# DDR32SS0_CTLPHY_WRAP_CTL_CFG_CTLCFG register map
Vendor: Texas Instruments
Registers are 32-bit, read-write, reset 0x0 unless marked. A register's access mark holds for its fields unless they carry their own. Offsets are as the file gives them; [hi:lo] are bit positions; lines under a group give offsets from that group; {n}, {i} and the like mark numbered series.

## DDR32SS0_CTLPHY_WRAP_CTL_CFG_CTLCFG (part 2 of 11)
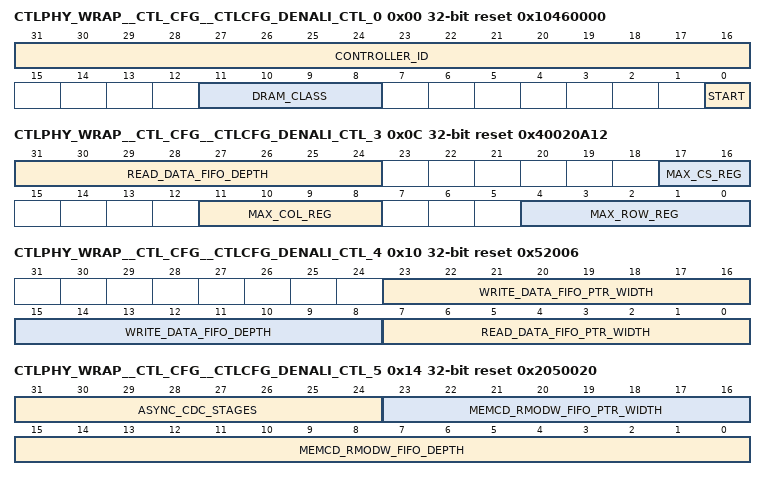
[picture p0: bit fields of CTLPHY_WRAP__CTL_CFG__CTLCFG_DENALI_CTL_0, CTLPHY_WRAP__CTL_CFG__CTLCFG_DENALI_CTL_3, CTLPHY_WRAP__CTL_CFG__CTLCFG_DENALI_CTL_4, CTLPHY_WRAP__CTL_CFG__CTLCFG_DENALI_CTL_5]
0x00 CTLPHY_WRAP__CTL_CFG__CTLCFG_DENALI_CTL_0 access per field reset 0x10460000
  [31:16] CONTROLLER_ID ro — Holds the controller product id number. READ-ONLY
  [11:8] DRAM_CLASS rw — Defines the class of DRAM memory which is connected to the controller.
  [0] START rw — Initiate command processing in the controller. Set to 1 to initiate.
0x04 CTLPHY_WRAP__CTL_CFG__CTLCFG_DENALI_CTL_1 ro reset 0x617AD652
  [31:0] CONTROLLER_VERSION_0 — Holds the controller version id. READ-ONLY
0x08 CTLPHY_WRAP__CTL_CFG__CTLCFG_DENALI_CTL_2 ro reset 0x409E81
  [31:0] CONTROLLER_VERSION_1 — Holds the controller version id. READ-ONLY
0x0C CTLPHY_WRAP__CTL_CFG__CTLCFG_DENALI_CTL_3 ro reset 0x40020A12
  [31:24] READ_DATA_FIFO_DEPTH — Reports the depth of the controller core read data queue. READ-ONLY
  [17:16] MAX_CS_REG — Holds the maximum number of chip selects available. READ-ONLY
  [11:8] MAX_COL_REG — Holds the maximum width of column address in DRAMs. READ-ONLY
  [4:0] MAX_ROW_REG — Holds the maximum width of memory address bus. READ-ONLY
0x10 CTLPHY_WRAP__CTL_CFG__CTLCFG_DENALI_CTL_4 ro reset 0x52006
  [23:16] WRITE_DATA_FIFO_PTR_WIDTH — Reports the width of the controller core write data latency queue pointer. READ-ONLY
  [15:8] WRITE_DATA_FIFO_DEPTH — Reports the depth of the controller core write data latency queue. READ-ONLY
  [7:0] READ_DATA_FIFO_PTR_WIDTH — Reports the width of the controller core read data queue pointer. READ-ONLY
0x14 CTLPHY_WRAP__CTL_CFG__CTLCFG_DENALI_CTL_5 ro reset 0x2050020
  [31:24] ASYNC_CDC_STAGES — Reports the number of synchronizer delays specified for the asynchronous boundary crossings. READ-ONLY
  [23:16] MEMCD_RMODW_FIFO_PTR_WIDTH — Reports the width of the controller core read/modify/write FIFO pointer. READ-ONLY
  [15:0] MEMCD_RMODW_FIFO_DEPTH — Reports the depth of the controller core read/modify/write FIFO. READ-ONLY
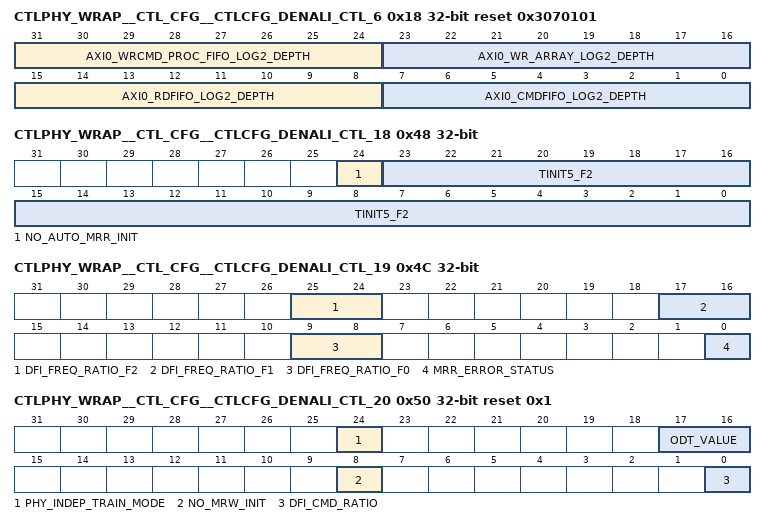
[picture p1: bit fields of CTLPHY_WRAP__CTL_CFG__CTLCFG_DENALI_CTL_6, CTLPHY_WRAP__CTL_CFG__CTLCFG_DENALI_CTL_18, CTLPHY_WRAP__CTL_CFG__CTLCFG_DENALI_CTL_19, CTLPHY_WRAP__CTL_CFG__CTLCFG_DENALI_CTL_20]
0x18 CTLPHY_WRAP__CTL_CFG__CTLCFG_DENALI_CTL_6 ro reset 0x3070101
  [31:24] AXI0_WRCMD_PROC_FIFO_LOG2_DEPTH — Reports the depth of the AXI port 0 write command processing FIFO. Value is the log2 value of the depth. READ-ONLY
  [23:16] AXI0_WR_ARRAY_LOG2_DEPTH — Reports the depth of the AXI port 0 write data array. Value is the log2 value of the depth. READ-ONLY
  [15:8] AXI0_RDFIFO_LOG2_DEPTH — Reports the depth of the AXI port 0 read data FIFO. Value is the log2 value of the depth. READ-ONLY
  [7:0] AXI0_CMDFIFO_LOG2_DEPTH — Reports the depth of the AXI port 0 command FIFO. Value is the log2 value of the depth. READ-ONLY
0x1C CTLPHY_WRAP__CTL_CFG__CTLCFG_DENALI_CTL_7
  [23:0] TINIT_F0 — DRAM TINIT value in cycles. FC=0
{0x0+4i} CTLPHY_WRAP__CTL_CFG__CTLCFG_DENALI_CTL_{i} (i=8..10)
  [23:0] TINIT{i-5}_F0 — DRAM TINIT{i-5} value in cycles. FC=0
0x2C CTLPHY_WRAP__CTL_CFG__CTLCFG_DENALI_CTL_11
  [23:0] TINIT_F1 — DRAM TINIT value in cycles. FC=1
{0x0+4i} CTLPHY_WRAP__CTL_CFG__CTLCFG_DENALI_CTL_{i} (i=12..14)
  [23:0] TINIT{i-9}_F1 — DRAM TINIT{i-9} value in cycles. FC=1
0x3C CTLPHY_WRAP__CTL_CFG__CTLCFG_DENALI_CTL_15
  [23:0] TINIT_F2 — DRAM TINIT value in cycles. FC=2
0x40 CTLPHY_WRAP__CTL_CFG__CTLCFG_DENALI_CTL_16
  [23:0] TINIT3_F2 — DRAM TINIT3 value in cycles. FC=2
0x44 CTLPHY_WRAP__CTL_CFG__CTLCFG_DENALI_CTL_17
  [23:0] TINIT4_F2 — DRAM TINIT4 value in cycles. FC=2
0x48 CTLPHY_WRAP__CTL_CFG__CTLCFG_DENALI_CTL_18
  [24] NO_AUTO_MRR_INIT — Disable MRR commands during initialization. Set to 1 to disable.
  [23:0] TINIT5_F2 — DRAM TINIT5 value in cycles. FC=2
0x4C CTLPHY_WRAP__CTL_CFG__CTLCFG_DENALI_CTL_19 access per field
  [25:24] DFI_FREQ_RATIO_F2 rw — Defines how dfi_freq_ratio is driven on the DFI bus. For LPDDR5, specifies the DFI clock to WCK ratio. For all other memory classes, specifies the controller clock to DFI PHY clock ratio. Program to zero for a 1:1 ratio, one for a 1:2 ratio, and two for a 1:4 ratio. FC=2
  [17:16] DFI_FREQ_RATIO_F1 rw — Defines how dfi_freq_ratio is driven on the DFI bus. For LPDDR5, specifies the DFI clock to WCK ratio. For all other memory classes, specifies the controller clock to DFI PHY clock ratio. Program to zero for a 1:1 ratio, one for a 1:2 ratio, and two for a 1:4 ratio. FC=1
  [9:8] DFI_FREQ_RATIO_F0 rw — Defines how dfi_freq_ratio is driven on the DFI bus. For LPDDR5, specifies the DFI clock to WCK ratio. For all other memory classes, specifies the controller clock to DFI PHY clock ratio. Program to zero for a 1:1 ratio, one for a 1:2 ratio, and two for a 1:4 ratio. FC=0
  [0] MRR_ERROR_STATUS ro — Indicates that an MRR was issued while in self-refresh. Value of 1 indicates a violation. READ-ONLY
0x50 CTLPHY_WRAP__CTL_CFG__CTLCFG_DENALI_CTL_20 access per field reset 0x1
  [24] PHY_INDEP_TRAIN_MODE rw — Enable PHY independent training mode commands during initialization. Set to 1 to enable.
  [17:16] ODT_VALUE rw — When using LPDDR4, this value will be driven out on the dfi_odt signal.
  [8] NO_MRW_INIT rw — Disable MRW commands during initialization. Set to 1 to disable.
  [0] DFI_CMD_RATIO ro — Indicates the controller clock to DFI PHY clock ratio for the DFI command interface. For LPDDR5, this is always a 1:1 ratio. For all other memory classes, this will be the same as the dfi_freq_ratio. Zero specifies a 1:1 ratio and one specifies a 1:2 ratio. READ-ONLY
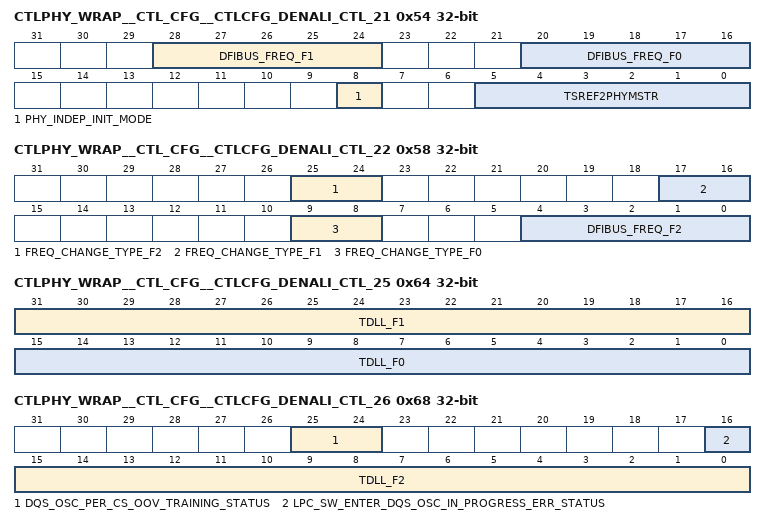
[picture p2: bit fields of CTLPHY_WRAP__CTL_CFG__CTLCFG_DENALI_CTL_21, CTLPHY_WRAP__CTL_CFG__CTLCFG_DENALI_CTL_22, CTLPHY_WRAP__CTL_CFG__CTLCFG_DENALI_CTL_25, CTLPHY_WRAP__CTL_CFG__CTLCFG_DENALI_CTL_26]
0x54 CTLPHY_WRAP__CTL_CFG__CTLCFG_DENALI_CTL_21
  [28:24] DFIBUS_FREQ_F1 — Defines the DFI bus frequency. FC=1
  [20:16] DFIBUS_FREQ_F0 — Defines the DFI bus frequency. FC=0
  [8] PHY_INDEP_INIT_MODE — Enable PHY independent initailization mode commands during initialization. Set to 1 to enable.
  [5:0] TSREF2PHYMSTR — Specifies the minimum time after a self-refresh exit command on the DFI bus that the Controller will wait for the PHY to assert the dfi_phymstr_req signal, before completing other commands. Used when the low power control logic is expected to pass control to the PHY for training when exiting SREF.
0x58 CTLPHY_WRAP__CTL_CFG__CTLCFG_DENALI_CTL_22
  [25:24] FREQ_CHANGE_TYPE_F2 — Defines the encoded frequency driven out on the cntrl_freq_change_req_type signal during a frequency change operation. FC=2
  [17:16] FREQ_CHANGE_TYPE_F1 — Defines the encoded frequency driven out on the cntrl_freq_change_req_type signal during a frequency change operation. FC=1
  [9:8] FREQ_CHANGE_TYPE_F0 — Defines the encoded frequency driven out on the cntrl_freq_change_req_type signal during a frequency change operation. FC=0
  [4:0] DFIBUS_FREQ_F2 — Defines the DFI bus frequency. FC=2
0x5C CTLPHY_WRAP__CTL_CFG__CTLCFG_DENALI_CTL_23
  [31:0] TRST_PWRON — Duration of memory reset during power-on initialization.
0x60 CTLPHY_WRAP__CTL_CFG__CTLCFG_DENALI_CTL_24
  [31:0] CKE_INACTIVE — Number of cycles after reset before CKE will be active.
0x64 CTLPHY_WRAP__CTL_CFG__CTLCFG_DENALI_CTL_25
  [31:16] TDLL_F1 — DRAM TDLL value in cycles. FC=1
  [15:0] TDLL_F0 — DRAM TDLL value in cycles. FC=0
0x68 CTLPHY_WRAP__CTL_CFG__CTLCFG_DENALI_CTL_26 access per field
  [25:24] DQS_OSC_PER_CS_OOV_TRAINING_STATUS ro — Set the CS information for which DQS oscillator is having out of variance value. READ-ONLY
  [16] LPC_SW_ENTER_DQS_OSC_IN_PROGRESS_ERR_STATUS ro — Error response for Software issued Low power command while DQS Oscillator is in progress. READ-ONLY
  [15:0] TDLL_F2 rw — DRAM TDLL value in cycles. FC=2
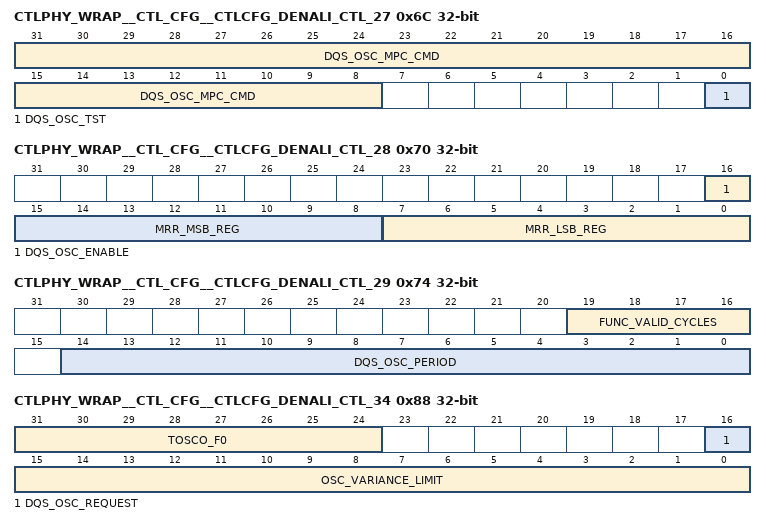
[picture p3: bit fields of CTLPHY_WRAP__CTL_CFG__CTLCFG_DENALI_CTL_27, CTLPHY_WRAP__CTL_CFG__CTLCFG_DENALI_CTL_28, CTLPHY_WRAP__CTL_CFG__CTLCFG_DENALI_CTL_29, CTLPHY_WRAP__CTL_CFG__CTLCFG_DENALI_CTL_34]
0x6C CTLPHY_WRAP__CTL_CFG__CTLCFG_DENALI_CTL_27
  [31:8] DQS_OSC_MPC_CMD — Set MPC encoding for DQS Oscillator TEST mode.
  [0] DQS_OSC_TST — Enable DQS Oscillator TEST mode.
0x70 CTLPHY_WRAP__CTL_CFG__CTLCFG_DENALI_CTL_28
  [16] DQS_OSC_ENABLE — Enable DQS oscillator measurement function in DRAM. Set to 1 to enable.
  [15:8] MRR_MSB_REG — Set MSB MRR register number for DQS Oscillator TEST mode.
  [7:0] MRR_LSB_REG — Set LSB MRR register number for DQS Oscillator TEST mode.
0x74 CTLPHY_WRAP__CTL_CFG__CTLCFG_DENALI_CTL_29
  [19:16] FUNC_VALID_CYCLES — Number of cycles to hold dfi_function_valid asserted.
  [14:0] DQS_OSC_PERIOD — Number of cycles to run the oscillator measurement. Must reflect cycles programmed into mode register.
0x78 CTLPHY_WRAP__CTL_CFG__CTLCFG_DENALI_CTL_30
  [31:0] DQS_OSC_NORM_THRESHOLD — Number of long counts until the normal priority request is asserted for DQS Oscillator.
0x7C CTLPHY_WRAP__CTL_CFG__CTLCFG_DENALI_CTL_31
  [31:0] DQS_OSC_HIGH_THRESHOLD — Number of long counts until the high priority request is asserted for DQS Oscillator.
0x80 CTLPHY_WRAP__CTL_CFG__CTLCFG_DENALI_CTL_32
  [31:0] DQS_OSC_TIMEOUT — Number of long counts until the timeout is asserted for DQS Oscillator.
0x84 CTLPHY_WRAP__CTL_CFG__CTLCFG_DENALI_CTL_33
  [31:0] DQS_OSC_PROMOTE_THRESHOLD — Number of long counts until a software request for the DQS Oscillator is promoted to high priority.
0x88 CTLPHY_WRAP__CTL_CFG__CTLCFG_DENALI_CTL_34 access per field
  [31:24] TOSCO_F0 rw — Number of cycles for tOSCO timing parameter, the time for the DQS Oscillator measurement to be available in the mode registers. FC=0
  [16] DQS_OSC_REQUEST wo — Software request for DQS Oscillator measurement function in DRAM. WRITE-ONLY
  [15:0] OSC_VARIANCE_LIMIT rw — Allowed difference between base value and DQS Oscillator measurement.
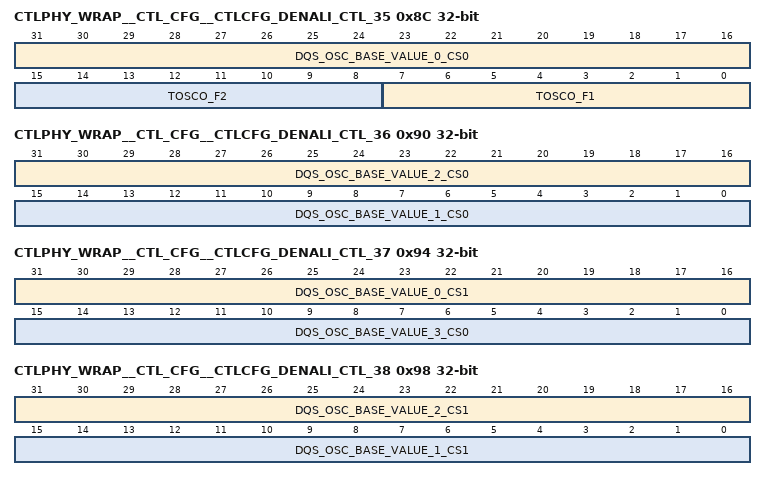
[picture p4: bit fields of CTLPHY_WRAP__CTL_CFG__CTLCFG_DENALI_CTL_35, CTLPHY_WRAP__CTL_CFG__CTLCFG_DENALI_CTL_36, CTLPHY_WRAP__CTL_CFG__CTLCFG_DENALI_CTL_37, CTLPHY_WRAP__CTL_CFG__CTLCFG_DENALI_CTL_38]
0x8C CTLPHY_WRAP__CTL_CFG__CTLCFG_DENALI_CTL_35 access per field
  [31:16] DQS_OSC_BASE_VALUE_0_CS0 ro — Base value for device 0 on chip 0. READ-ONLY DEV=0
  [15:8] TOSCO_F2 rw — Number of cycles for tOSCO timing parameter, the time for the DQS Oscillator measurement to be available in the mode registers. FC=2
  [7:0] TOSCO_F1 rw — Number of cycles for tOSCO timing parameter, the time for the DQS Oscillator measurement to be available in the mode registers. FC=1
0x90 CTLPHY_WRAP__CTL_CFG__CTLCFG_DENALI_CTL_36 ro
  [31:16] DQS_OSC_BASE_VALUE_2_CS0 — Base value for device 2 on chip 0. READ-ONLY DEV=2
  [15:0] DQS_OSC_BASE_VALUE_1_CS0 — Base value for device 1 on chip 0. READ-ONLY DEV=1
0x94 CTLPHY_WRAP__CTL_CFG__CTLCFG_DENALI_CTL_37 ro
  [31:16] DQS_OSC_BASE_VALUE_0_CS1 — Base value for device 0 on chip 1. READ-ONLY DEV=0
  [15:0] DQS_OSC_BASE_VALUE_3_CS0 — Base value for device 3 on chip 0. READ-ONLY DEV=3
0x98 CTLPHY_WRAP__CTL_CFG__CTLCFG_DENALI_CTL_38 ro
  [31:16] DQS_OSC_BASE_VALUE_2_CS1 — Base value for device 2 on chip 1. READ-ONLY DEV=2
  [15:0] DQS_OSC_BASE_VALUE_1_CS1 — Base value for device 1 on chip 1. READ-ONLY DEV=1
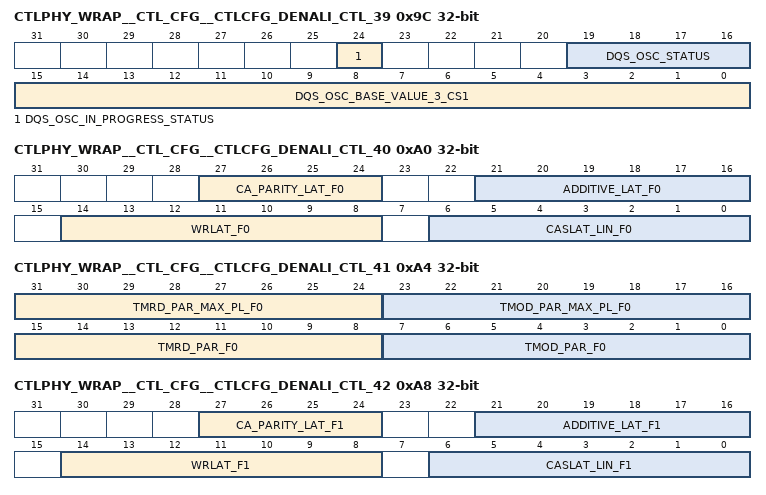
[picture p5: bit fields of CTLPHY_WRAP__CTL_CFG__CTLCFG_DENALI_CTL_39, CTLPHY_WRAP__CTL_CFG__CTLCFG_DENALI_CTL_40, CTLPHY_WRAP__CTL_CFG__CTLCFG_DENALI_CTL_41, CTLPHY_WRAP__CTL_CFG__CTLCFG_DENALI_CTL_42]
0x9C CTLPHY_WRAP__CTL_CFG__CTLCFG_DENALI_CTL_39 ro
  [24] DQS_OSC_IN_PROGRESS_STATUS — DQS Oscillator is in progress.Set '1' DQS OSC is in progress READ-ONLY
  [19:16] DQS_OSC_STATUS — Holds the overflow and out of variance status associated with the resp. interrupts. Bit [0] set indicates overflow of DQS oscillator,bit [1] set indicates overflow of WCKO oscillator,bit [2] set indicates oov of DQS oscillator,bit [3] set indicates oov of WCKO oscillator. READ-ONLY
  [15:0] DQS_OSC_BASE_VALUE_3_CS1 — Base value for device 3 on chip 1. READ-ONLY DEV=3
0xA0 CTLPHY_WRAP__CTL_CFG__CTLCFG_DENALI_CTL_40
  [27:24] CA_PARITY_LAT_F0 — DRAM CA parity latency value in cycles. FC=0
  [21:16] ADDITIVE_LAT_F0 — DRAM additive latency value in cycles. FC=0
  [14:8] WRLAT_F0 — DRAM WRLAT value in cycles. FC=0
  [6:0] CASLAT_LIN_F0 — Sets latency from read command send to data receive from/to controller. Bit [0] is half-cycle increment and the upper bits define memory CAS latency for the controller. FC=0
0xA4 CTLPHY_WRAP__CTL_CFG__CTLCFG_DENALI_CTL_41
  [31:24] TMRD_PAR_MAX_PL_F0 — DRAM TMRD value with maximum CA parity for frequency copy 4 in cycles. Used during changes of CA parity latency value in DRAM. FC=0
  [23:16] TMOD_PAR_MAX_PL_F0 — DRAM TMOD value with maximum CA parity for frequency copy 4 in cycles. Used during changes of CA parity latency value in DRAM. FC=0
  [15:8] TMRD_PAR_F0 — DRAM TMRD value when CA parity is enabled in cycles. FC=0
  [7:0] TMOD_PAR_F0 — DRAM TMOD value when CA parity is enabled in cycles. FC=0
0xA8 CTLPHY_WRAP__CTL_CFG__CTLCFG_DENALI_CTL_42
  [27:24] CA_PARITY_LAT_F1 — DRAM CA parity latency value in cycles. FC=1
  [21:16] ADDITIVE_LAT_F1 — DRAM additive latency value in cycles. FC=1
  [14:8] WRLAT_F1 — DRAM WRLAT value in cycles. FC=1
  [6:0] CASLAT_LIN_F1 — Sets latency from read command send to data receive from/to controller. Bit [0] is half-cycle increment and the upper bits define memory CAS latency for the controller. FC=1
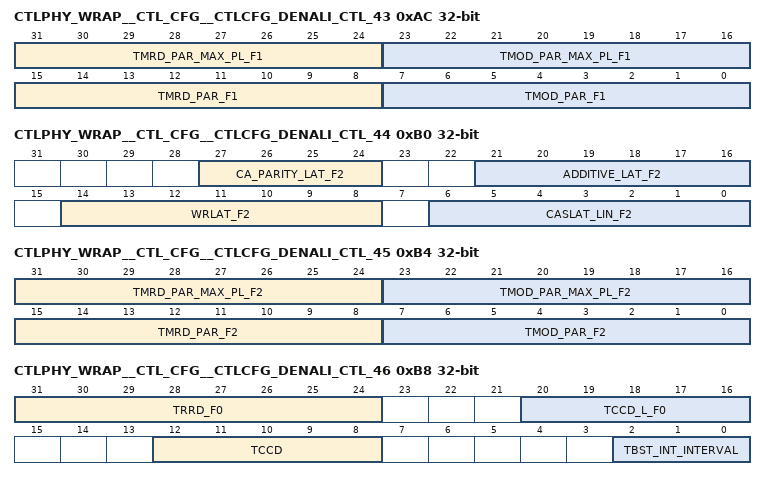
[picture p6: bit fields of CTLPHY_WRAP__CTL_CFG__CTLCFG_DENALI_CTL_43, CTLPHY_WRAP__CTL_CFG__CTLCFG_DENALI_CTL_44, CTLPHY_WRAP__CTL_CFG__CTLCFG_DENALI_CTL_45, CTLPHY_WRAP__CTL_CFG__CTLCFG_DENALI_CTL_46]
0xAC CTLPHY_WRAP__CTL_CFG__CTLCFG_DENALI_CTL_43
  [31:24] TMRD_PAR_MAX_PL_F1 — DRAM TMRD value with maximum CA parity for frequency copy 4 in cycles. Used during changes of CA parity latency value in DRAM. FC=1
  [23:16] TMOD_PAR_MAX_PL_F1 — DRAM TMOD value with maximum CA parity for frequency copy 4 in cycles. Used during changes of CA parity latency value in DRAM. FC=1
  [15:8] TMRD_PAR_F1 — DRAM TMRD value when CA parity is enabled in cycles. FC=1
  [7:0] TMOD_PAR_F1 — DRAM TMOD value when CA parity is enabled in cycles. FC=1
0xB0 CTLPHY_WRAP__CTL_CFG__CTLCFG_DENALI_CTL_44
  [27:24] CA_PARITY_LAT_F2 — DRAM CA parity latency value in cycles. FC=2
  [21:16] ADDITIVE_LAT_F2 — DRAM additive latency value in cycles. FC=2
  [14:8] WRLAT_F2 — DRAM WRLAT value in cycles. FC=2
  [6:0] CASLAT_LIN_F2 — Sets latency from read command send to data receive from/to controller. Bit [0] is half-cycle increment and the upper bits define memory CAS latency for the controller. FC=2
0xB4 CTLPHY_WRAP__CTL_CFG__CTLCFG_DENALI_CTL_45
  [31:24] TMRD_PAR_MAX_PL_F2 — DRAM TMRD value with maximum CA parity for frequency copy 4 in cycles. Used during changes of CA parity latency value in DRAM. FC=2
  [23:16] TMOD_PAR_MAX_PL_F2 — DRAM TMOD value with maximum CA parity for frequency copy 4 in cycles. Used during changes of CA parity latency value in DRAM. FC=2
  [15:8] TMRD_PAR_F2 — DRAM TMRD value when CA parity is enabled in cycles. FC=2
  [7:0] TMOD_PAR_F2 — DRAM TMOD value when CA parity is enabled in cycles. FC=2
0xB8 CTLPHY_WRAP__CTL_CFG__CTLCFG_DENALI_CTL_46
  [31:24] TRRD_F0 — DRAM TRRD value in cycles. FC=0
  [20:16] TCCD_L_F0 — DRAM CAS-to-CAS value within the same bank group in cycles. FC=0
  [12:8] TCCD — DRAM CAS-to-CAS value in cycles.
  [2:0] TBST_INT_INTERVAL — DRAM burst interrupt interval value in cycles.
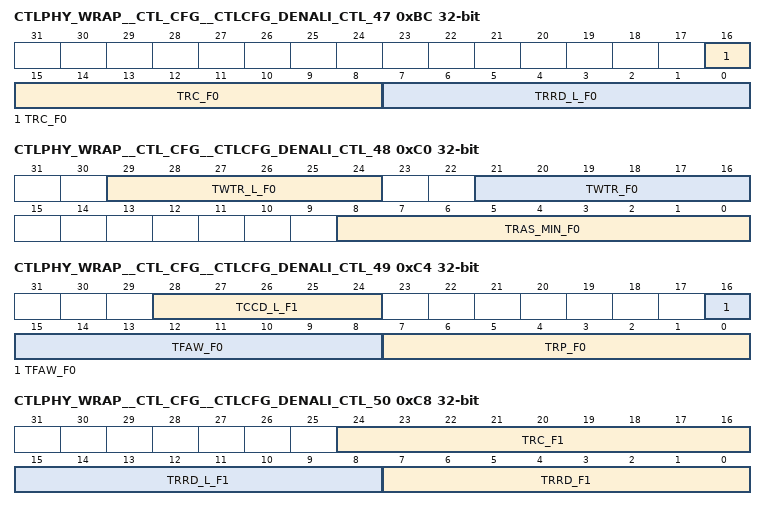
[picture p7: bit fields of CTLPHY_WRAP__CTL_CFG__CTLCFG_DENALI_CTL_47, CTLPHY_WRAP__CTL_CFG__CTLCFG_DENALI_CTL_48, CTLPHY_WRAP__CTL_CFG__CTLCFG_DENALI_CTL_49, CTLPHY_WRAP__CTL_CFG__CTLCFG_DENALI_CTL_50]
0xBC CTLPHY_WRAP__CTL_CFG__CTLCFG_DENALI_CTL_47
  [16:8] TRC_F0 — DRAM TRC value in cycles. FC=0
  [7:0] TRRD_L_F0 — DRAM TRRD_L value in cycles. FC=0
0xC0 CTLPHY_WRAP__CTL_CFG__CTLCFG_DENALI_CTL_48
  [29:24] TWTR_L_F0 — DRAM TWTR_L value in cycles. FC=0
  [21:16] TWTR_F0 — DRAM TWTR value in cycles. FC=0
  [8:0] TRAS_MIN_F0 — DRAM TRAS_MIN value in cycles. FC=0
0xC4 CTLPHY_WRAP__CTL_CFG__CTLCFG_DENALI_CTL_49
  [28:24] TCCD_L_F1 — DRAM CAS-to-CAS value within the same bank group in cycles. FC=1
  [16:8] TFAW_F0 — DRAM TFAW value in cycles. FC=0
  [7:0] TRP_F0 — DRAM TRP value in cycles. FC=0
0xC8 CTLPHY_WRAP__CTL_CFG__CTLCFG_DENALI_CTL_50
  [24:16] TRC_F1 — DRAM TRC value in cycles. FC=1
  [15:8] TRRD_L_F1 — DRAM TRRD_L value in cycles. FC=1
  [7:0] TRRD_F1 — DRAM TRRD value in cycles. FC=1
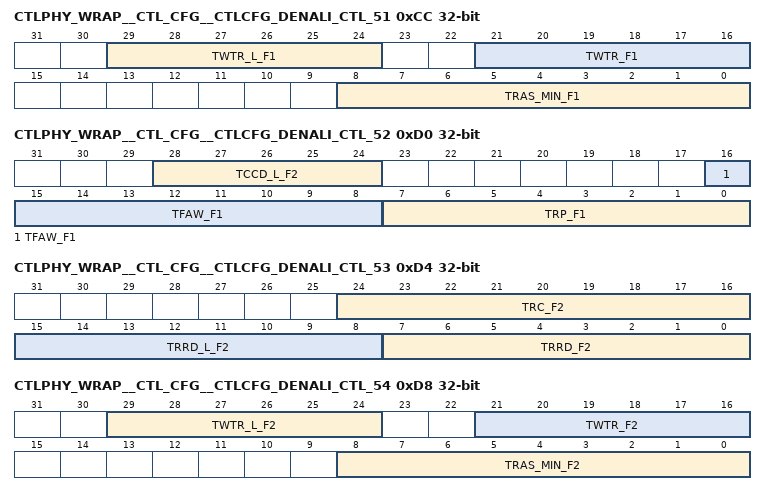
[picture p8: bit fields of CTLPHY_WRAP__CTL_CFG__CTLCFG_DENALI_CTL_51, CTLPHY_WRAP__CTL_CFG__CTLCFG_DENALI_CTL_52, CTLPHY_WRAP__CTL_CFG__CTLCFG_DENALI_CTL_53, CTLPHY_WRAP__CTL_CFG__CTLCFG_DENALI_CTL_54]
0xCC CTLPHY_WRAP__CTL_CFG__CTLCFG_DENALI_CTL_51
  [29:24] TWTR_L_F1 — DRAM TWTR_L value in cycles. FC=1
  [21:16] TWTR_F1 — DRAM TWTR value in cycles. FC=1
  [8:0] TRAS_MIN_F1 — DRAM TRAS_MIN value in cycles. FC=1
0xD0 CTLPHY_WRAP__CTL_CFG__CTLCFG_DENALI_CTL_52
  [28:24] TCCD_L_F2 — DRAM CAS-to-CAS value within the same bank group in cycles. FC=2
  [16:8] TFAW_F1 — DRAM TFAW value in cycles. FC=1
  [7:0] TRP_F1 — DRAM TRP value in cycles. FC=1
0xD4 CTLPHY_WRAP__CTL_CFG__CTLCFG_DENALI_CTL_53
  [24:16] TRC_F2 — DRAM TRC value in cycles. FC=2
  [15:8] TRRD_L_F2 — DRAM TRRD_L value in cycles. FC=2
  [7:0] TRRD_F2 — DRAM TRRD value in cycles. FC=2
0xD8 CTLPHY_WRAP__CTL_CFG__CTLCFG_DENALI_CTL_54
  [29:24] TWTR_L_F2 — DRAM TWTR_L value in cycles. FC=2
  [21:16] TWTR_F2 — DRAM TWTR value in cycles. FC=2
  [8:0] TRAS_MIN_F2 — DRAM TRAS_MIN value in cycles. FC=2
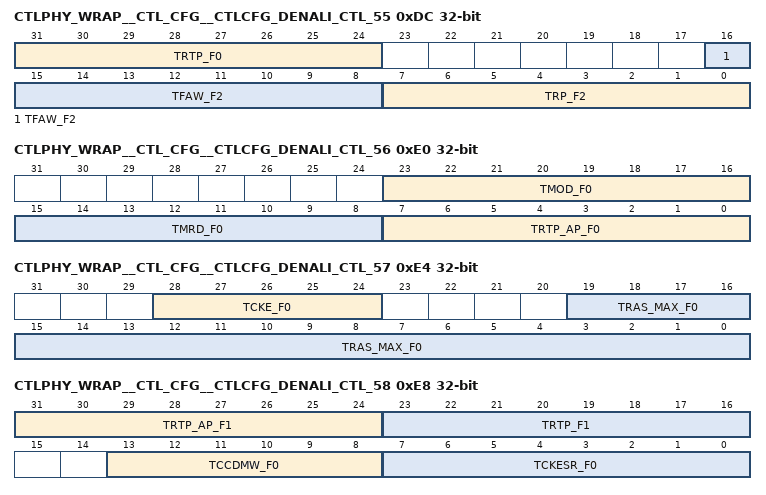
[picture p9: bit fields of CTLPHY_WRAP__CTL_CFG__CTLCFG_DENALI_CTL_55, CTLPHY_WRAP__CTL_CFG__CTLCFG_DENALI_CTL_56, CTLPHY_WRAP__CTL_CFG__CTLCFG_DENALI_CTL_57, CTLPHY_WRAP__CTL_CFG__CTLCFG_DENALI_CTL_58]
0xDC CTLPHY_WRAP__CTL_CFG__CTLCFG_DENALI_CTL_55
  [31:24] TRTP_F0 — DRAM TRTP value in cycles. FC=0
  [16:8] TFAW_F2 — DRAM TFAW value in cycles. FC=2
  [7:0] TRP_F2 — DRAM TRP value in cycles. FC=2
0xE0 CTLPHY_WRAP__CTL_CFG__CTLCFG_DENALI_CTL_56
  [23:16] TMOD_F0 — Number of cycles after MRS command and before any other command. FC=0
  [15:8] TMRD_F0 — DRAM TMRD value in cycles. FC=0
  [7:0] TRTP_AP_F0 — DRAM TRTP for auto-precharge value in cycles. FC=0
0xE4 CTLPHY_WRAP__CTL_CFG__CTLCFG_DENALI_CTL_57
  [28:24] TCKE_F0 — Minimum CKE pulse width. FC=0
  [19:0] TRAS_MAX_F0 — DRAM TRAS_MAX value in cycles. FC=0
0xE8 CTLPHY_WRAP__CTL_CFG__CTLCFG_DENALI_CTL_58
  [31:24] TRTP_AP_F1 — DRAM TRTP for auto-precharge value in cycles. FC=1
  [23:16] TRTP_F1 — DRAM TRTP value in cycles. FC=1
  [13:8] TCCDMW_F0 — DRAM CAS-to-CAS masked write value in cycles. FC=0
  [7:0] TCKESR_F0 — Minimum CKE low pulse width during a self-refresh. FC=0
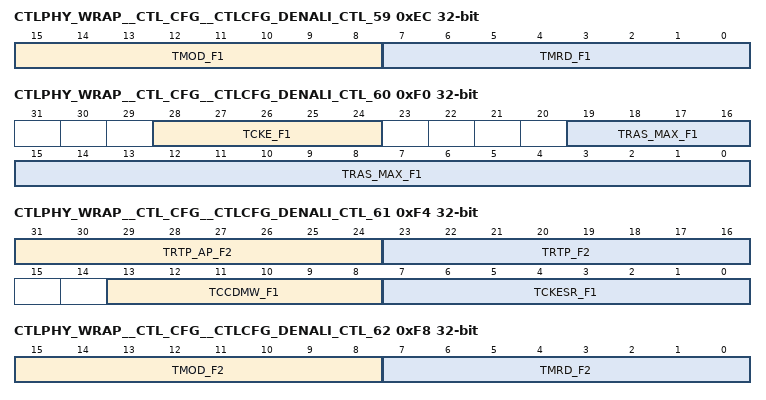
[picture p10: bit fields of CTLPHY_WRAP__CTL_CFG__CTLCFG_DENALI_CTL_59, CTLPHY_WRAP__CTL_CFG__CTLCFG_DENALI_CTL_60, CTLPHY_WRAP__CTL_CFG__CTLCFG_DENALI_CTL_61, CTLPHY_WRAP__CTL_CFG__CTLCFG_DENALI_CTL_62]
0xEC CTLPHY_WRAP__CTL_CFG__CTLCFG_DENALI_CTL_59
  [15:8] TMOD_F1 — Number of cycles after MRS command and before any other command. FC=1
  [7:0] TMRD_F1 — DRAM TMRD value in cycles. FC=1
0xF0 CTLPHY_WRAP__CTL_CFG__CTLCFG_DENALI_CTL_60
  [28:24] TCKE_F1 — Minimum CKE pulse width. FC=1
  [19:0] TRAS_MAX_F1 — DRAM TRAS_MAX value in cycles. FC=1
0xF4 CTLPHY_WRAP__CTL_CFG__CTLCFG_DENALI_CTL_61
  [31:24] TRTP_AP_F2 — DRAM TRTP for auto-precharge value in cycles. FC=2
  [23:16] TRTP_F2 — DRAM TRTP value in cycles. FC=2
  [13:8] TCCDMW_F1 — DRAM CAS-to-CAS masked write value in cycles. FC=1
  [7:0] TCKESR_F1 — Minimum CKE low pulse width during a self-refresh. FC=1
0xF8 CTLPHY_WRAP__CTL_CFG__CTLCFG_DENALI_CTL_62
  [15:8] TMOD_F2 — Number of cycles after MRS command and before any other command. FC=2
  [7:0] TMRD_F2 — DRAM TMRD value in cycles. FC=2
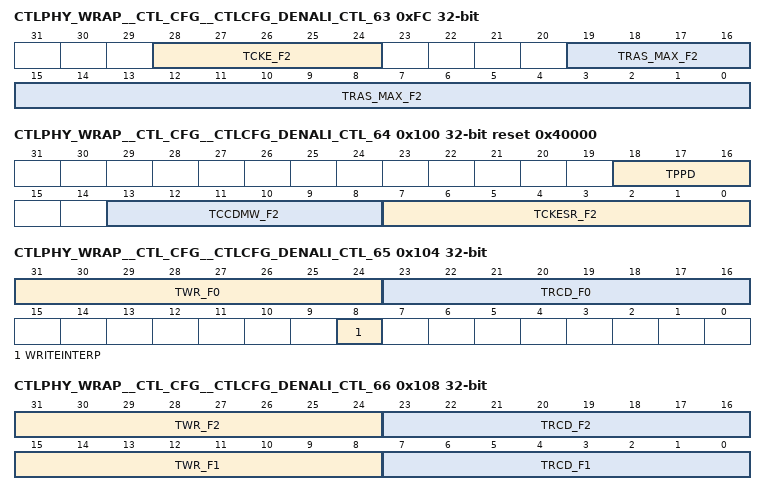
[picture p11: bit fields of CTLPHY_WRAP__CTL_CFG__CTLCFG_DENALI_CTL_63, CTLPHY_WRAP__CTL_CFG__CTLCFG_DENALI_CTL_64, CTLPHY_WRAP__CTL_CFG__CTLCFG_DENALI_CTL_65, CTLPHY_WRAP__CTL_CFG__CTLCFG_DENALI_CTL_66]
0xFC CTLPHY_WRAP__CTL_CFG__CTLCFG_DENALI_CTL_63
  [28:24] TCKE_F2 — Minimum CKE pulse width. FC=2
  [19:0] TRAS_MAX_F2 — DRAM TRAS_MAX value in cycles. FC=2
0x100 CTLPHY_WRAP__CTL_CFG__CTLCFG_DENALI_CTL_64 reset 0x40000
  [18:16] TPPD — DRAM TPPD value in cycles.
  [13:8] TCCDMW_F2 — DRAM CAS-to-CAS masked write value in cycles. FC=2
  [7:0] TCKESR_F2 — Minimum CKE low pulse width during a self-refresh. FC=2
0x104 CTLPHY_WRAP__CTL_CFG__CTLCFG_DENALI_CTL_65
  [31:24] TWR_F0 — DRAM TWR value in cycles. FC=0
  [23:16] TRCD_F0 — DRAM TRCD value in cycles. FC=0
  [8] WRITEINTERP — Allow controller to interrupt a write burst to the DRAMs with a read command. Set to 1 to allow interruption.
0x108 CTLPHY_WRAP__CTL_CFG__CTLCFG_DENALI_CTL_66
  [31:24] TWR_F2 — DRAM TWR value in cycles. FC=2
  [23:16] TRCD_F2 — DRAM TRCD value in cycles. FC=2
  [15:8] TWR_F1 — DRAM TWR value in cycles. FC=1
  [7:0] TRCD_F1 — DRAM TRCD value in cycles. FC=1
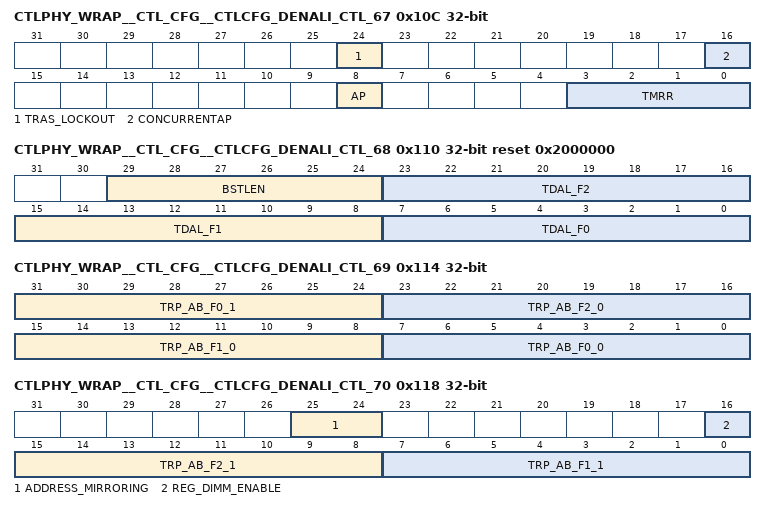
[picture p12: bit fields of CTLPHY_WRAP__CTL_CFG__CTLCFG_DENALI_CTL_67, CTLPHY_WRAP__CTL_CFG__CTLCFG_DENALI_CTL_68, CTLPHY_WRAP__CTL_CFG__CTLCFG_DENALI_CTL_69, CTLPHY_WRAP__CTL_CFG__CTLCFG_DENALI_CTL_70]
0x10C CTLPHY_WRAP__CTL_CFG__CTLCFG_DENALI_CTL_67
  [24] TRAS_LOCKOUT — IF the DRAM supports it, this allows the controller to execute auto pre-charge commands before the TRAS_MIN parameter expires. Set to 1 to enable.
  [16] CONCURRENTAP — IF the DRAM supports it, this allows the controller to issue commands to other banks while a bank is in auto pre-charge. Set to 1 to enable.
  [8] AP — Enable auto pre-charge mode of controller. Set to 1 to enable.
  [3:0] TMRR — DRAM TMRR value in cycles.
0x110 CTLPHY_WRAP__CTL_CFG__CTLCFG_DENALI_CTL_68 reset 0x2000000
  [29:24] BSTLEN — Encoded burst length sent to DRAMs during initialization. Program to 1 for BL2, program to 2 for BL4, program to 3 for BL8, program to 4 for BL16, or program to 5 for BL32. All other settings are reserved.
  [23:16] TDAL_F2 — DRAM TDAL value in cycles. FC=2
  [15:8] TDAL_F1 — DRAM TDAL value in cycles. FC=1
  [7:0] TDAL_F0 — DRAM TDAL value in cycles. FC=0
0x114 CTLPHY_WRAP__CTL_CFG__CTLCFG_DENALI_CTL_69
  [31:24] TRP_AB_F0_1 — DRAM TRP all bank value in cycles. FC=0
  [23:16] TRP_AB_F2_0 — DRAM TRP all bank value in cycles. FC=2
  [15:8] TRP_AB_F1_0 — DRAM TRP all bank value in cycles. FC=1
  [7:0] TRP_AB_F0_0 — DRAM TRP all bank value in cycles. FC=0
0x118 CTLPHY_WRAP__CTL_CFG__CTLCFG_DENALI_CTL_70
  [25:24] ADDRESS_MIRRORING — Indicates which chip selects support address mirroring. Bit [0] controls cs0, bit [1] controls cs1, etc. Set each bit to 1 to enable.
  [16] REG_DIMM_ENABLE — Enable registered DIMM operation of the controller. Set to 1 to enable.
  [15:8] TRP_AB_F2_1 — DRAM TRP all bank value in cycles. FC=2
  [7:0] TRP_AB_F1_1 — DRAM TRP all bank value in cycles. FC=1
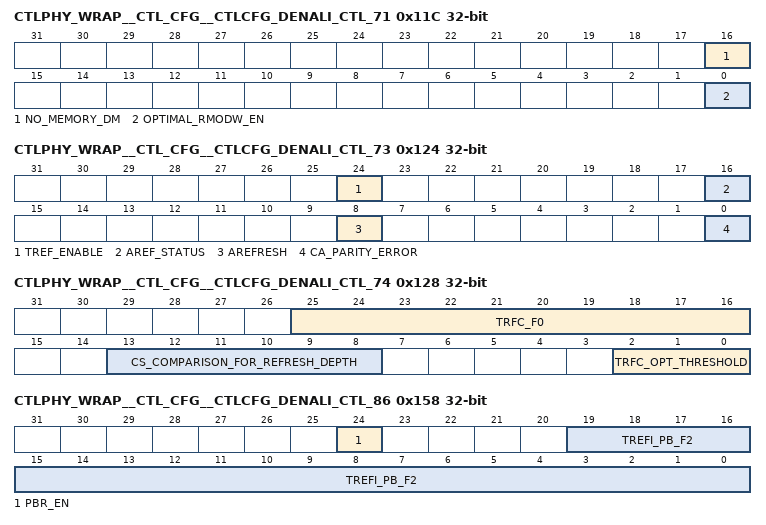
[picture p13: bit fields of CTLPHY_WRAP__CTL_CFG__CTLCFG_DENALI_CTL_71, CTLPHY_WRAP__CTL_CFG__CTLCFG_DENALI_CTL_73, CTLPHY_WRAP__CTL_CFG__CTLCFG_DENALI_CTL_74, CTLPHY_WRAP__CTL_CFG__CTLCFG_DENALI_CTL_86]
0x11C CTLPHY_WRAP__CTL_CFG__CTLCFG_DENALI_CTL_71
  [16] NO_MEMORY_DM — Indicates that the external DRAM does not support DM masking. Set to 1 for no DM masking at the DRAM.
  [0] OPTIMAL_RMODW_EN — Enables optimized RMODW logic in the controller. A value of 1 enables optimized RMODW operation. All RMODW operations are still supported in a non-optimal manner when the value is 0.
0x120 CTLPHY_WRAP__CTL_CFG__CTLCFG_DENALI_CTL_72
  [25:0] CA_PARITY_ERROR_INJECT — Selects bit to corrupt on the CA bus for CA parity error injection.
0x124 CTLPHY_WRAP__CTL_CFG__CTLCFG_DENALI_CTL_73 access per field
  [24] TREF_ENABLE rw — Issue auto-refresh commands to the DRAMs at the interval defined in the TREF parameter. Set to 1 to enable.
  [16] AREF_STATUS ro — Indicates a SR error associated with the AREF interrupt. Value of 1 indicates a violation. READ-ONLY
  [8] AREFRESH wo — Initiate auto-refresh at the end of the current burst boundary. Set to 1 to trigger. WRITE-ONLY
  [0] CA_PARITY_ERROR ro — Contains one hot indication of registered DIMM parity errors. Value of 1 indicates an error on that DIMM. READ-ONLY
0x128 CTLPHY_WRAP__CTL_CFG__CTLCFG_DENALI_CTL_74
  [25:16] TRFC_F0 — DRAM TRFC value in cycles. FC=0
  [13:8] CS_COMPARISON_FOR_REFRESH_DEPTH — Defines the number of entries of the command queue that the refresh logic will consider for sending a refresh command. A non-zero value limits the decode to a subset of the full command pipeline.
  [2:0] TRFC_OPT_THRESHOLD — Number of clocks before TRFC expires when the refresh task will deassert its request for optimal command to command turn-around timing.
0x12C CTLPHY_WRAP__CTL_CFG__CTLCFG_DENALI_CTL_75
  [19:0] TREF_F0 — DRAM TREF value in cycles. FC=0
0x130 CTLPHY_WRAP__CTL_CFG__CTLCFG_DENALI_CTL_76
  [9:0] TRFC_F1 — DRAM TRFC value in cycles. FC=1
0x134 CTLPHY_WRAP__CTL_CFG__CTLCFG_DENALI_CTL_77
  [19:0] TREF_F1 — DRAM TREF value in cycles. FC=1
0x138 CTLPHY_WRAP__CTL_CFG__CTLCFG_DENALI_CTL_78
  [9:0] TRFC_F2 — DRAM TRFC value in cycles. FC=2
0x13C CTLPHY_WRAP__CTL_CFG__CTLCFG_DENALI_CTL_79
  [19:0] TREF_F2 — DRAM TREF value in cycles. FC=2
0x140 CTLPHY_WRAP__CTL_CFG__CTLCFG_DENALI_CTL_80
  [19:0] TREF_INTERVAL — Defines the cycles between refreshes to different chip selects.
0x144 CTLPHY_WRAP__CTL_CFG__CTLCFG_DENALI_CTL_81
  [9:0] TRFC_PB_F0 — DRAM TRFC_PB value in cycles. FC=0
0x148 CTLPHY_WRAP__CTL_CFG__CTLCFG_DENALI_CTL_82
  [19:0] TREFI_PB_F0 — DRAM TREFI_PB value in cycles. FC=0
0x14C CTLPHY_WRAP__CTL_CFG__CTLCFG_DENALI_CTL_83
  [9:0] TRFC_PB_F1 — DRAM TRFC_PB value in cycles. FC=1
0x150 CTLPHY_WRAP__CTL_CFG__CTLCFG_DENALI_CTL_84
  [19:0] TREFI_PB_F1 — DRAM TREFI_PB value in cycles. FC=1
0x154 CTLPHY_WRAP__CTL_CFG__CTLCFG_DENALI_CTL_85
  [9:0] TRFC_PB_F2 — DRAM TRFC_PB value in cycles. FC=2
0x158 CTLPHY_WRAP__CTL_CFG__CTLCFG_DENALI_CTL_86
  [24] PBR_EN — Enables the per-bank refresh feature. Set to 1 to enable.
  [19:0] TREFI_PB_F2 — DRAM TREFI_PB value in cycles. FC=2
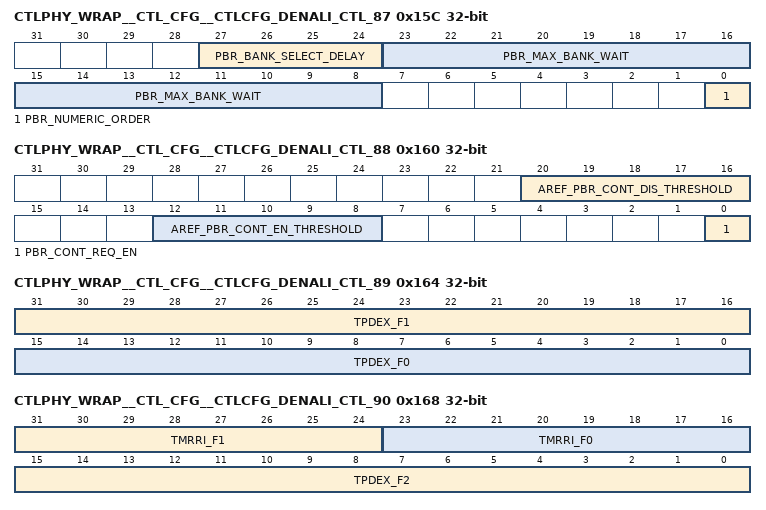
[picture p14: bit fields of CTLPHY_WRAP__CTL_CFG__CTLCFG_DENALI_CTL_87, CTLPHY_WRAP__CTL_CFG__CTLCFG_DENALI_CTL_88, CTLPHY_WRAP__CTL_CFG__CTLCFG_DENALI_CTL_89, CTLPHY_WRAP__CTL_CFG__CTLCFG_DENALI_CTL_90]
0x15C CTLPHY_WRAP__CTL_CFG__CTLCFG_DENALI_CTL_87
  [27:24] PBR_BANK_SELECT_DELAY — Defines the PBR bank select to command delay, the time from bank selection to when the command queue bank selection logic is guaranteed to have blocked the bank.
  [23:8] PBR_MAX_BANK_WAIT — Defines the maximum number of cycles that the PBR module will wait for Strategy to release the target bank until the PBR will assert the inhibit and close the target bank.
  [0] PBR_NUMERIC_ORDER — Enables the PBR to run REFpb commands in numeric bank order [0,1,2,3, etc.] When disabled, the order may be modified if supported by the memory type. Set to 1 to enable.
0x160 CTLPHY_WRAP__CTL_CFG__CTLCFG_DENALI_CTL_88
  [20:16] AREF_PBR_CONT_DIS_THRESHOLD — Sets the auto-refresh request count threshold when the PBR continuous refresh request enable will be deasserted.
  [12:8] AREF_PBR_CONT_EN_THRESHOLD — Sets the auto-refresh request count threshold when the PBR continuous refresh request enable will be asserted.
  [0] PBR_CONT_REQ_EN — Enables the per-bank refresh continuous request feature. Set to 1 to enable.
0x164 CTLPHY_WRAP__CTL_CFG__CTLCFG_DENALI_CTL_89
  [31:16] TPDEX_F1 — DRAM TPDEX value in cycles. FC=1
  [15:0] TPDEX_F0 — DRAM TPDEX value in cycles. FC=0
0x168 CTLPHY_WRAP__CTL_CFG__CTLCFG_DENALI_CTL_90
  [31:24] TMRRI_F1 — DRAM TMRRI value in cycles. FC=1
  [23:16] TMRRI_F0 — DRAM TMRRI value in cycles. FC=0
  [15:0] TPDEX_F2 — DRAM TPDEX value in cycles. FC=2
0x16C CTLPHY_WRAP__CTL_CFG__CTLCFG_DENALI_CTL_91
  [28:24] TMRWCKEL_F0 — DRAM TMRWCKEL value in cycles. FC=0
  [20:16] TCKEHCS_F0 — DRAM TCKEHCS value in cycles. FC=0
  [12:8] TCKELCS_F0 — DRAM TCKELCS value in cycles. FC=0
  [7:0] TMRRI_F2 — DRAM TMRRI value in cycles. FC=2
0x170 CTLPHY_WRAP__CTL_CFG__CTLCFG_DENALI_CTL_92
  [28:24] TMRWCKEL_F1 — DRAM TMRWCKEL value in cycles. FC=1
  [20:16] TCKEHCS_F1 — DRAM TCKEHCS value in cycles. FC=1
  [12:8] TCKELCS_F1 — DRAM TCKELCS value in cycles. FC=1
  [3:0] TZQCKE_F0 — DRAM TZQCKE value in cycles. FC=0
0x174 CTLPHY_WRAP__CTL_CFG__CTLCFG_DENALI_CTL_93
  [28:24] TMRWCKEL_F2 — DRAM TMRWCKEL value in cycles. FC=2
  [20:16] TCKEHCS_F2 — DRAM TCKEHCS value in cycles. FC=2
  [12:8] TCKELCS_F2 — DRAM TCKELCS value in cycles. FC=2
  [3:0] TZQCKE_F1 — DRAM TZQCKE value in cycles. FC=1
0x178 CTLPHY_WRAP__CTL_CFG__CTLCFG_DENALI_CTL_94
  [28:24] TCSCKE_F1 — DRAM TCSCKE value in cycles. FC=1
  [16] CA_DEFAULT_VAL_F0 — Defines how unused address/command bits are driven. Set to 1 to use last value or clear to 0 to drive low. FC=0
  [12:8] TCSCKE_F0 — DRAM TCSCKE value in cycles. FC=0
  [3:0] TZQCKE_F2 — DRAM TZQCKE value in cycles. FC=2
0x17C CTLPHY_WRAP__CTL_CFG__CTLCFG_DENALI_CTL_95
  [16] CA_DEFAULT_VAL_F2 — Defines how unused address/command bits are driven. Set to 1 to use last value or clear to 0 to drive low. FC=2
  [12:8] TCSCKE_F2 — DRAM TCSCKE value in cycles. FC=2
  [0] CA_DEFAULT_VAL_F1 — Defines how unused address/command bits are driven. Set to 1 to use last value or clear to 0 to drive low. FC=1
{0x0+4i} CTLPHY_WRAP__CTL_CFG__CTLCFG_DENALI_CTL_{i} (i=96..98)
  [31:16] TXSNR_F{i-96} — DRAM TXSNR value in cycles. FC={i-96}
  [15:0] TXSR_F{i-96} — DRAM TXSR value in cycles. FC={i-96}
0x18C CTLPHY_WRAP__CTL_CFG__CTLCFG_DENALI_CTL_99
  [31:16] TXPR_F1 — DRAM TXPR value in cycles. This parameter defines reset exit time from CKE HIGH to a valid command. FC=1
  [15:0] TXPR_F0 — DRAM TXPR value in cycles. This parameter defines reset exit time from CKE HIGH to a valid command. FC=0
0x190 CTLPHY_WRAP__CTL_CFG__CTLCFG_DENALI_CTL_100
  [26:24] TESCKE_F0 — DRAM TESCKE value in cycles. FC=0
  [23:16] TSR_F0 — DRAM TSR value in cycles. FC=0
  [15:0] TXPR_F2 — DRAM TXPR value in cycles. This parameter defines reset exit time from CKE HIGH to a valid command. FC=2
0x194 CTLPHY_WRAP__CTL_CFG__CTLCFG_DENALI_CTL_101
  [28:24] TCKCKEL_F0 — DRAM TCKCKEL value in cycles. FC=0
  [20:16] TCKEHCMD_F0 — DRAM TCKEHCMD value in cycles. FC=0
  [12:8] TCKELCMD_F0 — DRAM TCKELCMD value in cycles. FC=0
  [4:0] TCSCKEH_F0 — DRAM TCSCKEH value in cycles. FC=0
0x198 CTLPHY_WRAP__CTL_CFG__CTLCFG_DENALI_CTL_102
  [28:24] TCSCKEH_F1 — DRAM TCSCKEH value in cycles. FC=1
  [18:16] TESCKE_F1 — DRAM TESCKE value in cycles. FC=1
  [15:8] TSR_F1 — DRAM TSR value in cycles. FC=1
  [4:0] TCKELPD_F0 — DRAM TCKELPD value in cycles. FC=0
0x19C CTLPHY_WRAP__CTL_CFG__CTLCFG_DENALI_CTL_103
  [28:24] TCKELPD_F1 — DRAM TCKELPD value in cycles. FC=1
  [20:16] TCKCKEL_F1 — DRAM TCKCKEL value in cycles. FC=1
  [12:8] TCKEHCMD_F1 — DRAM TCKEHCMD value in cycles. FC=1
  [4:0] TCKELCMD_F1 — DRAM TCKELCMD value in cycles. FC=1
0x1A0 CTLPHY_WRAP__CTL_CFG__CTLCFG_DENALI_CTL_104
  [28:24] TCKELCMD_F2 — DRAM TCKELCMD value in cycles. FC=2
  [20:16] TCSCKEH_F2 — DRAM TCSCKEH value in cycles. FC=2
  [10:8] TESCKE_F2 — DRAM TESCKE value in cycles. FC=2
  [7:0] TSR_F2 — DRAM TSR value in cycles. FC=2
0x1A4 CTLPHY_WRAP__CTL_CFG__CTLCFG_DENALI_CTL_105
  [28:24] TCMDCKE_F0 — DRAM TCMDCKE value in cycles. FC=0
  [20:16] TCKELPD_F2 — DRAM TCKELPD value in cycles. FC=2
  [12:8] TCKCKEL_F2 — DRAM TCKCKEL value in cycles. FC=2
  [4:0] TCKEHCMD_F2 — DRAM TCKEHCMD value in cycles. FC=2
0x1A8 CTLPHY_WRAP__CTL_CFG__CTLCFG_DENALI_CTL_106
  [24] SREFRESH_EXIT_NO_REFRESH — Disables the automatic refresh request associated with self-refresh exit. Set to 1 to disable.
  [16] PWRUP_SREFRESH_EXIT — Allow powerup via self-refresh instead of full memory initialization. Set to 1 to enable.
  [12:8] TCMDCKE_F2 — DRAM TCMDCKE value in cycles. FC=2
  [4:0] TCMDCKE_F1 — DRAM TCMDCKE value in cycles. FC=1
0x1AC CTLPHY_WRAP__CTL_CFG__CTLCFG_DENALI_CTL_107 access per field
  [30:24] DFS_STATUS rw — Contains status and interrupt information related to DFS. Bit [0] set indicates that the DFS request from the hardware interface was ignored because param_dfs_enable was zero or because another HWI-initiated DFS operation was already in progress. Bit [1] set indicates that a DFS operation initiated by the hardware interface was terminated because the PHY did not deassert dfi_init_complete within tDFI_INIT_START after the controller asserted dfi_init_start. Bit [2] set indicates that a hardware interface initiated DFS operation completed successfully. Bit [3] set indicates that the DFS command on the software interface was ignored either because param_dfs_enable was zero or because another SW-initiated DFS operation was already in progress. Bit [4] set indicates that a DFS operation initiated by the software interface was terminated because the PHY did not deassert dfi_init_complete within tDFI_INIT_START after the controller asserted dfi_init_start. Bit [5] set indicates that a software initiated DFS operation completed successfully. Bit [6] set indicates that the DFS logic entered the software wait state after a DFS operation completed. Clear this bit to allow the logic to exit this wait state.
  [20:16] DFS_CMD wo — lt Currently not supported gt DFS software command request interface. Bit [0] sends the DFS exit request when set. Bit [1] sends the DFS enter request when set. Bit [2] tells the controller to gate the memory clock before handing control to the PHY during a DFS operation. Bits [4
  [10:8] CKE_DELAY rw — Additional cycles to delay CKE for status reporting.
  [0] ENABLE_QUICK_SREFRESH rw — Allow user to interrupt memory initialization to enter self-refresh mode. Set to 1 to allow interruption.
0x1B0 CTLPHY_WRAP__CTL_CFG__CTLCFG_DENALI_CTL_108
  [23:8] DFS_PROMOTE_THRESHOLD_F0 — DFS promotion number of long counts until the high priority request is asserted for frequency copy 0. Applies to SW and HW DFS commands. FC=0
  [0] DFS_ZQ_EN — Enables ZQ calibration across all ranks during a DFS exit. Set to 1 to enable. Not valid when operating in ZQ background mode.
0x1B4 CTLPHY_WRAP__CTL_CFG__CTLCFG_DENALI_CTL_109
  [31:16] DFS_PROMOTE_THRESHOLD_F2 — DFS promotion number of long counts until the high priority request is asserted for frequency copy 2. Applies to SW and HW DFS commands. FC=2
  [15:0] DFS_PROMOTE_THRESHOLD_F1 — DFS promotion number of long counts until the high priority request is asserted for frequency copy 1. Applies to SW and HW DFS commands. FC=1
0x1B8 CTLPHY_WRAP__CTL_CFG__CTLCFG_DENALI_CTL_110 ro
  [2:0] ZQ_STATUS_LOG — Indicates what kind of ZQ command was terminated without execution that caused the ZQ status interrupt to assert. Bit [0] correlates to a ZQ cal init, reset, short or long command. Bit [1] correlates to a ZQ cal start command. Bit [2] correlates to a ZQ cal latch command. Value of 1 indicates that that type of command was received, but terminated without execution. READ-ONLY
0x1BC CTLPHY_WRAP__CTL_CFG__CTLCFG_DENALI_CTL_111
  [31:16] UPD_CTRLUPD_NORM_THRESHOLD_F0 — DFI control update number of long counts until the normal priority request is asserted. FC=0
0x1C0 CTLPHY_WRAP__CTL_CFG__CTLCFG_DENALI_CTL_112
  [31:16] UPD_CTRLUPD_TIMEOUT_F0 — DFI control update number of long counts until the timeout is asserted. FC=0
  [15:0] UPD_CTRLUPD_HIGH_THRESHOLD_F0 — DFI control update number of long counts until the high priority request is asserted. FC=0
0x1C4 CTLPHY_WRAP__CTL_CFG__CTLCFG_DENALI_CTL_113
  [31:16] UPD_PHYUPD_DFI_PROMOTE_THRESHOLD_F0 — DFI PHY update DFI promotion number of long counts until the high priority request is asserted. FC=0
  [15:0] UPD_CTRLUPD_SW_PROMOTE_THRESHOLD_F0 — DFI control update SW promotion number of long counts until the high priority request is asserted. FC=0
0x1C8 CTLPHY_WRAP__CTL_CFG__CTLCFG_DENALI_CTL_114
  [31:16] UPD_CTRLUPD_HIGH_THRESHOLD_F1 — DFI control update number of long counts until the high priority request is asserted. FC=1
  [15:0] UPD_CTRLUPD_NORM_THRESHOLD_F1 — DFI control update number of long counts until the normal priority request is asserted. FC=1
0x1CC CTLPHY_WRAP__CTL_CFG__CTLCFG_DENALI_CTL_115
  [31:16] UPD_CTRLUPD_SW_PROMOTE_THRESHOLD_F1 — DFI control update SW promotion number of long counts until the high priority request is asserted. FC=1
  [15:0] UPD_CTRLUPD_TIMEOUT_F1 — DFI control update number of long counts until the timeout is asserted. FC=1
0x1D0 CTLPHY_WRAP__CTL_CFG__CTLCFG_DENALI_CTL_116
  [31:16] UPD_CTRLUPD_NORM_THRESHOLD_F2 — DFI control update number of long counts until the normal priority request is asserted. FC=2
  [15:0] UPD_PHYUPD_DFI_PROMOTE_THRESHOLD_F1 — DFI PHY update DFI promotion number of long counts until the high priority request is asserted. FC=1
0x1D4 CTLPHY_WRAP__CTL_CFG__CTLCFG_DENALI_CTL_117
  [31:16] UPD_CTRLUPD_TIMEOUT_F2 — DFI control update number of long counts until the timeout is asserted. FC=2
  [15:0] UPD_CTRLUPD_HIGH_THRESHOLD_F2 — DFI control update number of long counts until the high priority request is asserted. FC=2
0x1D8 CTLPHY_WRAP__CTL_CFG__CTLCFG_DENALI_CTL_118
  [31:16] UPD_PHYUPD_DFI_PROMOTE_THRESHOLD_F2 — DFI PHY update DFI promotion number of long counts until the high priority request is asserted. FC=2
  [15:0] UPD_CTRLUPD_SW_PROMOTE_THRESHOLD_F2 — DFI control update SW promotion number of long counts until the high priority request is asserted. FC=2
0x1DC CTLPHY_WRAP__CTL_CFG__CTLCFG_DENALI_CTL_119
  [31:0] TDFI_PHYMSTR_MAX_F0 — Defines the DFI tPHYMSTR_MAX timing parameter [in DFI clocks], the maximum cycles that dfi_phymstr_req can be asserted following the assertion of dfi_phymstr_ack. If programmed to a non-zero, a timing violation will cause an interrupt and bit [0] set in the PHYMSTR_ERROR_STATUS parameter. FC=0
{0x0+4i} CTLPHY_WRAP__CTL_CFG__CTLCFG_DENALI_CTL_{i} (i=120..123)
  [31:0] TDFI_PHYMSTR_MAX_TYPE{i-120}_F0 — Defines the DFI 4.0v2 tPHYMSTR_MAX_TYPE{i-120} timing parameter [in DFI clocks], the maximum cycles that dfi_phymstr_req can be asserted following the assertion of dfi_phymstr_ack for dfi_phymstr_type={i-120}. If programmed to a non-zero, a timing violation will cause an interrupt and bit [0] set in the PHYMSTR_ERROR_STATUS parameter. FC=0
0x1F0 CTLPHY_WRAP__CTL_CFG__CTLCFG_DENALI_CTL_124
  [15:0] PHYMSTR_DFI4_PROMOTE_THRESHOLD_F0 — Defines the DFI[4.0 and 4.0v2] PHY controller request promotion number of regular [not long] counts until the high priority request is asserted. FC=0
0x1F4 CTLPHY_WRAP__CTL_CFG__CTLCFG_DENALI_CTL_125
  [19:0] TDFI_PHYMSTR_RESP_F0 — Defines the DFI tPHYMSTR_RESP timing parameter [in DFI clocks], the maximum cycles between a dfi_phymstr_req assertion and a dfi_phymstr_ack assertion. If programmed to a non-zero, a timing violation will cause an interrupt and bit [1] to be set to 1 in the PHYMSTR_ERROR_STATUS parameter. FC=0
0x1F8 CTLPHY_WRAP__CTL_CFG__CTLCFG_DENALI_CTL_126
  [31:0] TDFI_PHYMSTR_MAX_F1 — Defines the DFI tPHYMSTR_MAX timing parameter [in DFI clocks], the maximum cycles that dfi_phymstr_req can be asserted following the assertion of dfi_phymstr_ack. If programmed to a non-zero, a timing violation will cause an interrupt and bit [0] set in the PHYMSTR_ERROR_STATUS parameter. FC=1
{0x0+4i} CTLPHY_WRAP__CTL_CFG__CTLCFG_DENALI_CTL_{i} (i=127..130)
  [31:0] TDFI_PHYMSTR_MAX_TYPE{i-127}_F1 — Defines the DFI 4.0v2 tPHYMSTR_MAX_TYPE{i-127} timing parameter [in DFI clocks], the maximum cycles that dfi_phymstr_req can be asserted following the assertion of dfi_phymstr_ack for dfi_phymstr_type={i-127}. If programmed to a non-zero, a timing violation will cause an interrupt and bit [0] set in the PHYMSTR_ERROR_STATUS parameter. FC=1
0x20C CTLPHY_WRAP__CTL_CFG__CTLCFG_DENALI_CTL_131
  [15:0] PHYMSTR_DFI4_PROMOTE_THRESHOLD_F1 — Defines the DFI[4.0 and 4.0v2] PHY controller request promotion number of regular [not long] counts until the high priority request is asserted. FC=1
0x210 CTLPHY_WRAP__CTL_CFG__CTLCFG_DENALI_CTL_132
  [19:0] TDFI_PHYMSTR_RESP_F1 — Defines the DFI tPHYMSTR_RESP timing parameter [in DFI clocks], the maximum cycles between a dfi_phymstr_req assertion and a dfi_phymstr_ack assertion. If programmed to a non-zero, a timing violation will cause an interrupt and bit [1] to be set to 1 in the PHYMSTR_ERROR_STATUS parameter. FC=1
0x214 CTLPHY_WRAP__CTL_CFG__CTLCFG_DENALI_CTL_133
  [31:0] TDFI_PHYMSTR_MAX_F2 — Defines the DFI tPHYMSTR_MAX timing parameter [in DFI clocks], the maximum cycles that dfi_phymstr_req can be asserted following the assertion of dfi_phymstr_ack. If programmed to a non-zero, a timing violation will cause an interrupt and bit [0] set in the PHYMSTR_ERROR_STATUS parameter. FC=2
{0x0+4i} CTLPHY_WRAP__CTL_CFG__CTLCFG_DENALI_CTL_{i} (i=134..137)
  [31:0] TDFI_PHYMSTR_MAX_TYPE{i-134}_F2 — Defines the DFI 4.0v2 tPHYMSTR_MAX_TYPE{i-134} timing parameter [in DFI clocks], the maximum cycles that dfi_phymstr_req can be asserted following the assertion of dfi_phymstr_ack for dfi_phymstr_type={i-134}. If programmed to a non-zero, a timing violation will cause an interrupt and bit [0] set in the PHYMSTR_ERROR_STATUS parameter. FC=2
0x228 CTLPHY_WRAP__CTL_CFG__CTLCFG_DENALI_CTL_138
  [15:0] PHYMSTR_DFI4_PROMOTE_THRESHOLD_F2 — Defines the DFI[4.0 and 4.0v2] PHY controller request promotion number of regular [not long] counts until the high priority request is asserted. FC=2
0x22C CTLPHY_WRAP__CTL_CFG__CTLCFG_DENALI_CTL_139
  [24] PHYMSTR_NO_AREF — isables refreshes during the PHY controller interface sequence. Set to 1 to disable. Refreshes during reset are only supported for DFI 4.0 and this parameter may be set or cleared for DFI 4.0. For all other DFI versions, this parameter must be set to 1.
  [19:0] TDFI_PHYMSTR_RESP_F2 — Defines the DFI tPHYMSTR_RESP timing parameter [in DFI clocks], the maximum cycles between a dfi_phymstr_req assertion and a dfi_phymstr_ack assertion. If programmed to a non-zero, a timing violation will cause an interrupt and bit [1] to be set to 1 in the PHYMSTR_ERROR_STATUS parameter. FC=2
0x230 CTLPHY_WRAP__CTL_CFG__CTLCFG_DENALI_CTL_140 access per field
  [16] PHYMSTR_TRAIN_AFTER_INIT_COMPLETE rw — Defines how the PHY will use the PHY Controller Interface for training. Clear to 0 to perform training without the PHY Controller Interface, or set to 1 to use the PHY Controller Interface to gain control over the DFI bus after the dfi_init_complete signal assertion for the initial training. Default is cleared to 0.
  [8] PHYMSTR_DFI_VERSION_4P0V1 rw — Defines the version of the DFI 4.0 specification supported. Clear to 0 for DFI 4.0 version 2 PHY Controller Interface, or set to 1 for DFI 4.0 version 1 PHY Controller Interface. Default is cleared to 0 for version 2.
  [1:0] PHYMSTR_ERROR_STATUS ro — Identifies the source of any DFI PHY Controller Interface errors. Value of 1 indicates a timing violation of the associated timing parameter. Bit [0] set indicates a TDFI_PHYMSTR_MAX or TDFI_PHYMSTR_TYPEn_MAX parmaeter violation and bit [1] set indicates a TDFI_PHYMSTR_RESP parameter violation. READ-ONLY
0x234 CTLPHY_WRAP__CTL_CFG__CTLCFG_DENALI_CTL_141
  [23:0] MRR_TEMPCHK_NORM_THRESHOLD_F0 — MRR temp check number of long counts until the normal priority request is asserted. FC=0
0x238 CTLPHY_WRAP__CTL_CFG__CTLCFG_DENALI_CTL_142
  [23:0] MRR_TEMPCHK_HIGH_THRESHOLD_F0 — MRR temp check number of long counts until the high priority request is asserted. FC=0
0x23C CTLPHY_WRAP__CTL_CFG__CTLCFG_DENALI_CTL_143
  [23:0] MRR_TEMPCHK_TIMEOUT_F0 — MRR temp check number of long counts until the timeout is asserted. FC=0
0x240 CTLPHY_WRAP__CTL_CFG__CTLCFG_DENALI_CTL_144
  [23:0] MRR_TEMPCHK_NORM_THRESHOLD_F1 — MRR temp check number of long counts until the normal priority request is asserted. FC=1
0x244 CTLPHY_WRAP__CTL_CFG__CTLCFG_DENALI_CTL_145
  [23:0] MRR_TEMPCHK_HIGH_THRESHOLD_F1 — MRR temp check number of long counts until the high priority request is asserted. FC=1
0x248 CTLPHY_WRAP__CTL_CFG__CTLCFG_DENALI_CTL_146
  [23:0] MRR_TEMPCHK_TIMEOUT_F1 — MRR temp check number of long counts until the timeout is asserted. FC=1
0x24C CTLPHY_WRAP__CTL_CFG__CTLCFG_DENALI_CTL_147
  [23:0] MRR_TEMPCHK_NORM_THRESHOLD_F2 — MRR temp check number of long counts until the normal priority request is asserted. FC=2
0x250 CTLPHY_WRAP__CTL_CFG__CTLCFG_DENALI_CTL_148
  [23:0] MRR_TEMPCHK_HIGH_THRESHOLD_F2 — MRR temp check number of long counts until the high priority request is asserted. FC=2
0x254 CTLPHY_WRAP__CTL_CFG__CTLCFG_DENALI_CTL_149
  [24] PPR_CONTROL — Enables the post-package repair feature. Set to 1 to enable. This parameter may only be programmed before initialization begins.
  [23:0] MRR_TEMPCHK_TIMEOUT_F2 — MRR temp check number of long counts until the timeout is asserted. FC=2
0x258 CTLPHY_WRAP__CTL_CFG__CTLCFG_DENALI_CTL_150 access per field
  [15:8] PPR_COMMAND_MRW_REGNUM rw — Specifies the mode register to be used. Clear to 0 for MRW0 or program to 4 for MRW4. All other values are reserved..
  [2:0] PPR_COMMAND wo — Specifies the type of PPR command. Program to 1 for pre-charge all, program to 2 for MRW, program to 3 for activate, or program to 5 for write. All other values are reserved. WRITE-ONLY
0x25C CTLPHY_WRAP__CTL_CFG__CTLCFG_DENALI_CTL_151
  [16:0] PPR_COMMAND_MRW_DATA — Specifies the data for the mode register write.
0x260 CTLPHY_WRAP__CTL_CFG__CTLCFG_DENALI_CTL_152
  [27:24] PPR_BANK_ADDRESS — Specifies the bank for the row to be repaired.
  [17:0] PPR_ROW_ADDRESS — Specifies the encoded row address to be repaired.
0x264 CTLPHY_WRAP__CTL_CFG__CTLCFG_DENALI_CTL_153
  [0] PPR_CS_ADDRESS — Specifies the chip select for the row to be repaired.
{0x0+4i} CTLPHY_WRAP__CTL_CFG__CTLCFG_DENALI_CTL_{i} (i=154..157)
  [31:0] PPR_DATA_{i-154} — Holds the data pattern to be written to memory for all data phases. This is specific to DDR4 memories.
0x278 CTLPHY_WRAP__CTL_CFG__CTLCFG_DENALI_CTL_158 access per field
  [31:24] CKSRX_F0 rw — Clock stable delay on self-refresh exit. FC=0
  [23:16] CKSRE_F0 rw — Clock hold delay on self-refresh entry. FC=0
  [8] FM_OVRIDE_CONTROL rw — Enables the FM Override feature. Set to 1 to enable.
  [1:0] PPR_STATUS ro — Reports the status of the PPR operation. Bit [0] set indicates that PPR operations are now allowed and bit [1] set indicates if the last PPR command is complete. READ-ONLY
0x27C CTLPHY_WRAP__CTL_CFG__CTLCFG_DENALI_CTL_159
  [31:24] CKSRX_F2 — Clock stable delay on self-refresh exit. FC=2
  [23:16] CKSRE_F2 — Clock hold delay on self-refresh entry. FC=2
  [15:8] CKSRX_F1 — Clock stable delay on self-refresh exit. FC=1
  [7:0] CKSRE_F1 — Clock hold delay on self-refresh entry. FC=1
0x280 CTLPHY_WRAP__CTL_CFG__CTLCFG_DENALI_CTL_160 access per field
  [27:24] LPI_SR_SHORT_WAKEUP_F0 rw — Defines the DFI tLP_WAKEUP timing parameter [in DFI clocks] to be driven when LPDDR4 memory is in the self-refresh short state [with or without memory clock gating]. For LPDDR4, SR_SHORT is used to send few commands so this wakeup time must be cleared to ZERO and no LPI request needs to be asserted. FC=0
  [19:16] LPI_IDLE_WAKEUP_F0 rw — Defines the DFI tLP_CTRL_WAKEUP timing parameter [in DFI clocks] to be driven when controller is idle. FC=0
  [14:8] LP_CMD wo — Low power software command request interface. Bit [0] controls exit, bit [1] controls entry, bits [4:2] define the low power state, bit [5] controls memory clock gating, bit [6] controls controller clock gating, and bit [7] controls lock. WRITE-ONLY
  [1:0] LOWPOWER_REFRESH_ENABLE rw — Enable refreshes while in low power mode. Bit [0] controls cs0, bit [1] controls cs1, etc. Set each bit to 1 to disable.
